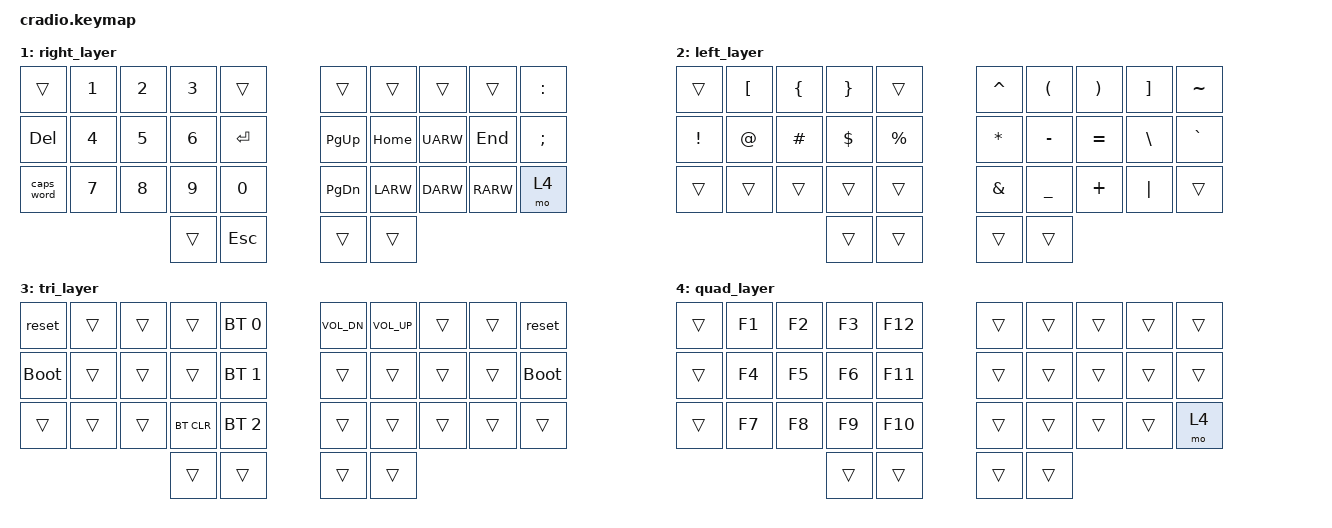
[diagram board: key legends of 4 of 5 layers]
// Copyright (c) 2022 The ZMK Contributors
// SPDX-License-Identifier: MIT

#include <behaviors.dtsi>
#include <dt-bindings/zmk/keys.h>
#include <dt-bindings/zmk/bt.h>

// Home row mods macro
#define HRML(k1,k2,k3,k4) &ht LSHFT k1  &ht LALT k2  &ht LCTRL k3  &ht LGUI k4
#define HRMR(k1,k2,k3,k4) &ht RGUI k1  &ht RCTRL k2  &ht RALT k3  &ht RSHFT k4

/ {
    behaviors {
        ht: hold_tap {
            label = "hold_tap";
            compatible = "zmk,behavior-hold-tap";
            #binding-cells = <2>;
            flavor = "tap-preferred";
            tapping-term-ms = <220>;
            quick-tap-ms = <150>;
            global-quick-tap;
            bindings = <&kp>, <&kp>;
        };
    };

    conditional_layers {
        compatible = "zmk,conditional-layers";
        tri_layer {
            if-layers = <1 2>;
            then-layer = <3>;
        };
    };

    keymap {
        compatible = "zmk,keymap";
        default_layer {
            bindings = <
        //╭──────────┬──────────┬──────────┬──────────┬──────────╮   ╭──────────┬──────────┬──────────┬──────────┬──────────╮
        //│  Q       │  W       │  E       │  R       │  T       │   │  Y       │  U       │  I       │  O       │  P       │
            &kp Q      &kp W      &kp E      &kp R      &kp T          &kp Y      &kp U      &kp I      &kp O      &kp P
        //├──────────┼──────────┼──────────┼──────────┼──────────┤   ├──────────┼──────────┼──────────┼──────────┼──────────┤
        //│  A       │  S       │  D       │  F       │  G       │   │  H       │  J       │  K       │  L       │ ' "      │
            HRML(A,        S,         D,         F)     &kp G          &kp H      HRMR(J,        K,         L,        SQT)
        //├──────────┼──────────┼──────────┼──────────┼──────────┤   ├──────────┼──────────┼──────────┼──────────┼──────────┤
        //│  Z       │  X       │  C       │  V       │  B       │   │  N       │  M       │ , <      │ . >      │ / ?      │
            &kp Z      &kp X      &kp C      &kp V      &kp B          &kp N      &kp M      &kp COMMA  &kp DOT    &kp FSLH
        //╰──────────┴──────────┴──────────┼──────────┼──────────┤   ├──────────┼──────────┼──────────┴──────────┴──────────╯
                                            &lt 2 TAB   &kp BSPC      &kp SPACE    &mo 1 
        //                                 ╰──────────┴──────────╯   ╰──────────┴──────────╯
            >;
        };

        right_layer {
            bindings = <
        //╭──────────┬──────────┬──────────┬──────────┬──────────╮   ╭──────────┬──────────┬──────────┬──────────┬──────────╮
        //│          │  1       │  2       │  3       │          │   │          │          │          │          │  :       │
            &trans     &kp N1     &kp N2     &kp N3     &trans         &trans     &trans     &trans     &trans      &kp COLON
        //├──────────┼──────────┼──────────┼──────────┼──────────┤   ├──────────┼──────────┼──────────┼──────────┼──────────┤
        //│ DELETE   │  4       │  5       │  6       │          │   │          │          │          │          │  ;       │
            &kp DEL    &kp N4     &kp N5     &kp N6    &kp ENTER      &kp PG_UP   &kp HOME   &kp UARW   &kp END     &kp SEMI
        //├──────────┼──────────┼──────────┼──────────┼──────────┤   ├──────────┼──────────┼──────────┼──────────┼──────────┤
        //│ CAPS     │  7       │  8       │  9       │  0       │   │          │          │          │          │          │
           &caps_word  &kp N7     &kp N8     &kp N9     &kp N0        &kp PG_DN   &kp LARW   &kp DARW   &kp RARW    &mo 4
        //╰──────────┴──────────┴──────────┼──────────┼──────────┤   ├──────────┼──────────┼──────────┴──────────┴──────────╯
                                             &trans      &kp ESC        &trans     &trans
        //                                 ╰──────────┴──────────╯   ╰──────────┴──────────╯
            >;
        };

        left_layer {
            bindings = <
        //╭──────────┬──────────┬──────────┬──────────┬──────────╮   ╭──────────┬──────────┬──────────┬──────────┬──────────╮
        //│          │  [       │  {       │  }       │          │   │  ^       │  (       │  )       │  ]       │  ~       │
            &trans     &kp LBKT   &kp LBRC   &kp RBRC   &trans         &kp CARET  &kp LPAR   &kp RPAR   &kp RBKT   &kp TILDE
        //├──────────┼──────────┼──────────┼──────────┼──────────┤   ├──────────┼──────────┼──────────┼──────────┼──────────┤
        //│  !       │  @       │  #       │  $       │  %       │   │  *       │  -       │  =       │  \       │  `       │
            &kp EXCL   &kp AT     &kp HASH   &kp DLLR   &kp PRCNT      &kp ASTRK  &kp MINUS  &kp EQUAL  &kp BSLH   &kp GRAVE
        //├──────────┼──────────┼──────────┼──────────┼──────────┤   ├──────────┼──────────┼──────────┼──────────┼──────────┤
        //│          │          │          │          │          │   │  &       │  _       │  +       │  │       │          │
            &trans     &trans     &trans     &trans     &trans         &kp AMPS   &kp UNDER  &kp PLUS   &kp PIPE   &trans
        //╰──────────┴──────────┴──────────┼──────────┼──────────┤   ├──────────┼──────────┼──────────┴──────────┴──────────╯
                                             &trans    &trans         &trans     &trans
        //                                 ╰──────────┴──────────╯   ╰──────────┴──────────╯
            >;
        };

        tri_layer {
            bindings = <
        //╭──────────┬──────────┬──────────┬──────────┬──────────╮   ╭──────────┬──────────┬──────────┬──────────┬──────────╮
        //│ RESET    │          │          │          │PROFILE 0 │   │          │          │          │          │  RESET   │
            &reset     &trans     &trans     &trans    &bt BT_SEL 0  &kp C_VOL_DN &kp C_VOL_UP &trans     &trans      &reset
        //├──────────┼──────────┼──────────┼──────────┼──────────┤   ├──────────┼──────────┼──────────┼──────────┼──────────┤
        //│BOOTLOADER│          │          │          │PROFILE 1 │   │          │          │          │          │BOOTLOADER│
          &bootloader  &trans     &trans     &trans    &bt BT_SEL 1    &trans     &trans     &trans     &trans    &bootloader
        //├──────────┼──────────┼──────────┼──────────┼──────────┤   ├──────────┼──────────┼──────────┼──────────┼──────────┤
        //│          │          │          │ CLEAR BT │PROFILE 2 │   │          │          │          │          │          │
            &trans     &trans     &trans    &bt BT_CLR &bt BT_SEL 2    &trans     &trans     &trans     &trans     &trans
        //╰──────────┴──────────┴──────────┼──────────┼──────────┤   ├──────────┼──────────┼──────────┴──────────┴──────────╯
                                             &trans     &trans         &trans     &trans
        //                                 ╰──────────┴──────────╯   ╰──────────┴──────────╯
            >;
        };
        
        quad_layer {
            bindings = <
        //╭──────────┬──────────┬──────────┬──────────┬──────────╮   ╭──────────┬──────────┬──────────┬──────────┬──────────╮
        //│          │  1       │  2       │  3       │          │   │          │          │          │          │          │
            &trans      &kp F1     &kp F2     &kp F3     &kp F12       &trans     &trans     &trans     &trans     &trans
        //├──────────┼──────────┼──────────┼──────────┼──────────┤   ├──────────┼──────────┼──────────┼──────────┼──────────┤
        //│          │  4       │  5       │  6       │          │   │          │          │          │          │          │
            &trans      &kp F4     &kp F5     &kp F6     &kp F11       &trans     &trans     &trans     &trans     &trans
        //├──────────┼──────────┼──────────┼──────────┼──────────┤   ├──────────┼──────────┼──────────┼──────────┼──────────┤
        //│          │  7       │  8       │  9       │  10      │   │          │          │          │          │          │
            &trans      &kp F7     &kp F8     &kp F9     &kp F10       &trans     &trans     &trans     &trans     &mo 4
        //╰──────────┴──────────┴──────────┼──────────┼──────────┤   ├──────────┼──────────┼──────────┴──────────┴──────────╯
                                             &trans      &trans        &trans     &trans
        //                                 ╰──────────┴──────────╯   ╰──────────┴──────────╯
            >;
        };
    };
};
